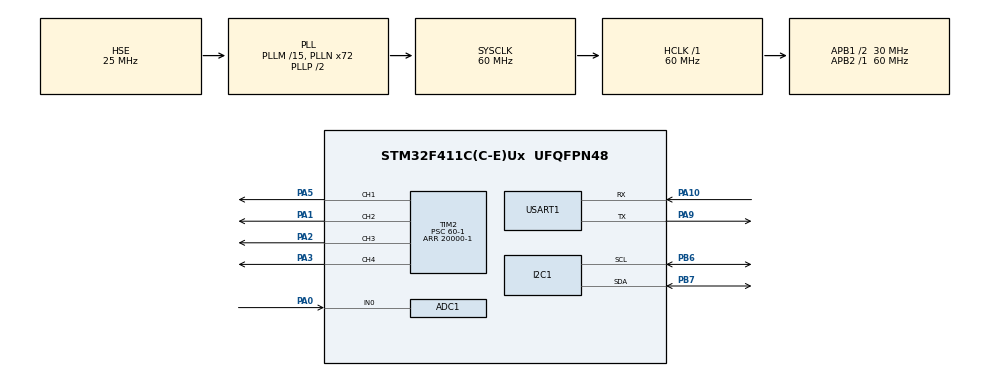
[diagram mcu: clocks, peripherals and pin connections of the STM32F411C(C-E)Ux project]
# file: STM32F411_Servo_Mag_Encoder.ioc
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ADC1.ClockPrescaler=ADC_CLOCK_SYNC_PCLK_DIV6
ADC1.ContinuousConvMode=ENABLE
ADC1.DMAContinuousRequests=ENABLE
ADC1.EOCSelection=ADC_EOC_SEQ_CONV
ADC1.NbrOfConversionFlag=1
ADC1.SamplingTime-0\#ChannelRegularConversion=ADC_SAMPLETIME_144CYCLES
ADC1.master=1
Dma.ADC1.0.Direction=DMA_PERIPH_TO_MEMORY
Dma.ADC1.0.FIFOMode=DMA_FIFOMODE_DISABLE
Dma.ADC1.0.Instance=DMA2_Stream0
Dma.ADC1.0.MemDataAlignment=DMA_MDATAALIGN_HALFWORD
Dma.ADC1.0.MemInc=DMA_MINC_ENABLE
Dma.ADC1.0.Mode=DMA_NORMAL
Dma.ADC1.0.PeriphDataAlignment=DMA_PDATAALIGN_HALFWORD
Dma.ADC1.0.PeriphInc=DMA_PINC_DISABLE
Dma.ADC1.0.Priority=DMA_PRIORITY_LOW
Dma.Request0=ADC1
Dma.Request1=USART1_RX
Dma.USART1_RX.1.Direction=DMA_PERIPH_TO_MEMORY
Dma.USART1_RX.1.FIFOMode=DMA_FIFOMODE_DISABLE
Dma.USART1_RX.1.Instance=DMA2_Stream2
Dma.USART1_RX.1.MemDataAlignment=DMA_MDATAALIGN_BYTE
Dma.USART1_RX.1.MemInc=DMA_MINC_ENABLE
Dma.USART1_RX.1.Mode=DMA_NORMAL
Dma.USART1_RX.1.PeriphDataAlignment=DMA_PDATAALIGN_BYTE
Dma.USART1_RX.1.PeriphInc=DMA_PINC_DISABLE
Dma.USART1_RX.1.Priority=DMA_PRIORITY_LOW
Mcu.Family=STM32F4
Mcu.Name=STM32F411C(C-E)Ux
Mcu.Package=UFQFPN48
NVIC.DMA2_Stream0_IRQn=true\:0\:0\:false\:false\:true\:false\:true\:true
NVIC.DMA2_Stream2_IRQn=true\:0\:0\:false\:false\:true\:false\:true\:true
NVIC.PriorityGroup=NVIC_PRIORITYGROUP_4
NVIC.USART1_IRQn=true\:0\:0\:false\:false\:true\:true\:true\:true
PA0-WKUP.Signal=ADCx_IN0
PA1.Signal=S_TIM2_CH2
PA10.Mode=Asynchronous
PA10.Signal=USART1_RX
PA13.Mode=Serial_Wire
PA13.Signal=SYS_JTMS-SWDIO
PA14.Mode=Serial_Wire
PA14.Signal=SYS_JTCK-SWCLK
PA2.Signal=S_TIM2_CH3
PA3.Signal=S_TIM2_CH4
PA5.Signal=S_TIM2_CH1_ETR
PA9.Mode=Asynchronous
PA9.Signal=USART1_TX
PB6.Mode=I2C
PB6.Signal=I2C1_SCL
PB7.Mode=I2C
PB7.Signal=I2C1_SDA
PC14-OSC32_IN.Mode=LSE-External-Oscillator
PC14-OSC32_IN.Signal=RCC_OSC32_IN
PC15-OSC32_OUT.Mode=LSE-External-Oscillator
PC15-OSC32_OUT.Signal=RCC_OSC32_OUT
PH0\ -\ OSC_IN.Mode=HSE-External-Oscillator
PH0\ -\ OSC_IN.Signal=RCC_OSC_IN
PH1\ -\ OSC_OUT.Mode=HSE-External-Oscillator
PH1\ -\ OSC_OUT.Signal=RCC_OSC_OUT
ProjectManager.HeapSize=0x200
ProjectManager.StackSize=0x400
ProjectManager.TargetToolchain=STM32CubeIDE
RCC.48MHZClocksFreq_Value=30000000
RCC.AHBFreq_Value=60000000
RCC.APB1CLKDivider=RCC_HCLK_DIV2
RCC.APB1Freq_Value=30000000
RCC.APB1TimFreq_Value=60000000
RCC.APB2Freq_Value=60000000
RCC.APB2TimFreq_Value=60000000
RCC.CortexFreq_Value=60000000
RCC.HCLKFreq_Value=60000000
RCC.HSE_VALUE=25000000
RCC.HSI_VALUE=16000000
RCC.PLLM=15
RCC.PLLN=72
RCC.PLLSourceVirtual=RCC_PLLSOURCE_HSE
RCC.SYSCLKFreq_VALUE=60000000
RCC.SYSCLKSource=RCC_SYSCLKSOURCE_PLLCLK
RCC.VCOOutputFreq_Value=120000000
SH.ADCx_IN0.0=ADC1_IN0,IN0
SH.S_TIM2_CH1_ETR.0=TIM2_CH1,PWM Generation1 CH1
SH.S_TIM2_CH2.0=TIM2_CH2,PWM Generation2 CH2
SH.S_TIM2_CH3.0=TIM2_CH3,PWM Generation3 CH3
SH.S_TIM2_CH4.0=TIM2_CH4,PWM Generation4 CH4
TIM2.Channel-PWM\ Generation1\ CH1=TIM_CHANNEL_1
TIM2.Channel-PWM\ Generation2\ CH2=TIM_CHANNEL_2
TIM2.Channel-PWM\ Generation3\ CH3=TIM_CHANNEL_3
TIM2.Channel-PWM\ Generation4\ CH4=TIM_CHANNEL_4
TIM2.Period=20000-1
TIM2.Prescaler=60-1
TIM2.Pulse-PWM\ Generation1\ CH1=1400
TIM2.Pulse-PWM\ Generation4\ CH4=1500
USART1.VirtualMode=VM_ASYNC
VP_TIM2_VS_ClockSourceINT.Mode=Internal
board=custom

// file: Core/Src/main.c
/* USER CODE BEGIN Header */
/**
  ******************************************************************************
  * @file           : main.c
  * @brief          : Main program body
  ******************************************************************************
  * @attention
  *
  * Copyright (c) 2024 STMicroelectronics.
  * All rights reserved.
  *
  * This software is licensed under terms that can be found in the LICENSE file
  * in the root directory of this software component.
  * If no LICENSE file comes with this software, it is provided AS-IS.
  *
  ******************************************************************************
  */
/* USER CODE END Header */
#include "main.h"
#include "adc.h"
#include "dma.h"
#include "i2c.h"
#include "tim.h"
#include "usart.h"
#include "gpio.h"

/* USER CODE BEGIN Includes */
#include "AS5600.h"
#include "stdio.h"
#include "stdint.h"
#include "string.h"
/* USER CODE END Includes */

/* USER CODE BEGIN PV */
uint16_t angle = 0;
uint8_t RxBuffer[10];

/* USER CODE END PV */

void SystemClock_Config(void);

int main(void)
{

  /* MCU Configuration--------------------------------------------------------*/

  /* Reset of all peripherals, Initializes the Flash interface and the Systick. */
  HAL_Init();

  /* Configure the system clock */
  SystemClock_Config();

  /* Initialize all configured peripherals */
  MX_GPIO_Init();
  MX_DMA_Init();
  MX_ADC1_Init();
  MX_TIM2_Init();
  MX_USART1_UART_Init();
  MX_I2C1_Init();
  /* USER CODE BEGIN 2 */
  HAL_TIM_PWM_Start(&htim2, TIM_CHANNEL_1);
  HAL_UART_Receive_DMA(&huart1, RxBuffer, sizeof(angle));
  HAL_Delay(20);

  /* USER CODE END 2 */

  /* Infinite loop */
  /* USER CODE BEGIN WHILE */
  while (1)
  {
	  //angle = AS5600_raw_angle_get(ENC_I2C_ADD);
	  HAL_Delay(100);
    /* USER CODE END WHILE */

  }
}

void SystemClock_Config(void)
{
  RCC_OscInitTypeDef RCC_OscInitStruct = {0};
  RCC_ClkInitTypeDef RCC_ClkInitStruct = {0};

  /** Configure the main internal regulator output voltage
  */
  __HAL_RCC_PWR_CLK_ENABLE();
  __HAL_PWR_VOLTAGESCALING_CONFIG(PWR_REGULATOR_VOLTAGE_SCALE1);

  /** Initializes the RCC Oscillators according to the specified parameters
  * in the RCC_OscInitTypeDef structure.
  */
  RCC_OscInitStruct.OscillatorType = RCC_OSCILLATORTYPE_HSE;
  RCC_OscInitStruct.HSEState = RCC_HSE_ON;
  RCC_OscInitStruct.PLL.PLLState = RCC_PLL_ON;
  RCC_OscInitStruct.PLL.PLLSource = RCC_PLLSOURCE_HSE;
  RCC_OscInitStruct.PLL.PLLM = 15;
  RCC_OscInitStruct.PLL.PLLN = 72;
  RCC_OscInitStruct.PLL.PLLP = RCC_PLLP_DIV2;
  RCC_OscInitStruct.PLL.PLLQ = 4;
  if (HAL_RCC_OscConfig(&RCC_OscInitStruct) != HAL_OK)
  {
    Error_Handler();
  }

  /** Initializes the CPU, AHB and APB buses clocks
  */
  RCC_ClkInitStruct.ClockType = RCC_CLOCKTYPE_HCLK|RCC_CLOCKTYPE_SYSCLK
                              |RCC_CLOCKTYPE_PCLK1|RCC_CLOCKTYPE_PCLK2;
  RCC_ClkInitStruct.SYSCLKSource = RCC_SYSCLKSOURCE_PLLCLK;
  RCC_ClkInitStruct.AHBCLKDivider = RCC_SYSCLK_DIV1;
  RCC_ClkInitStruct.APB1CLKDivider = RCC_HCLK_DIV2;
  RCC_ClkInitStruct.APB2CLKDivider = RCC_HCLK_DIV1;

  if (HAL_RCC_ClockConfig(&RCC_ClkInitStruct, FLASH_LATENCY_1) != HAL_OK)
  {
    Error_Handler();
  }
}

/* USER CODE BEGIN 4 */
void HAL_UART_RxCpltCallback(UART_HandleTypeDef *huart)
{
	HAL_UART_Receive_DMA(&huart1, (uint8_t*)&angle, sizeof(angle));
}
/* USER CODE END 4 */

void Error_Handler(void)
{
  __disable_irq();
  while (1)
  {
  }
}
